# STM32L4P5 register map
File version: 1.8
CPU: CM4 r0p1, little endian, MPU, FPU, 4 interrupt priority bits
Registers are 32-bit, read-write, reset 0x0 unless marked. A register's access mark holds for its fields unless they carry their own. Offsets are from the block's base; [hi:lo] are bit positions; 'fields as' and 'values as' point back to an identical list.

## IWDG — Independent watchdog
Base 0x40003000
0x00 KR wo — Key register
  [15:0] KEY — Key value (write only, read 0x0000)
    0x5555=Unlock (Enable access to PR, RLR and WINR registers); 0xAAAA=Feed watchdog with RLR register value; 0xCCCC=Start the watchdog
0x04 PR — Prescaler register
  [2:0] PR — Prescaler divider
    0=DivideBy4 (Divider /4); 1=DivideBy8 (Divider /8); 2=DivideBy16 (Divider /16); 3=DivideBy32 (Divider /32); 4=DivideBy64 (Divider /64); 5=DivideBy128 (Divider /128); other=DivideBy256 (Divider /256)
0x08 RLR reset 0xFFF — Reload register
  [11:0] RL — Watchdog counter reload value
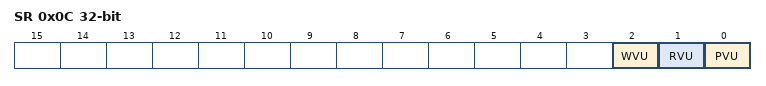
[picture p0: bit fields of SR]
0x0C SR ro — Status register
  [2] WVU — Watchdog counter window value update
  [1] RVU — Watchdog counter reload value update
  [0] PVU — Watchdog prescaler value update
0x10 WINR reset 0xFFF — Window register
  [11:0] WIN — Watchdog counter window value

## WWDG — System window watchdog
Base 0x40002C00
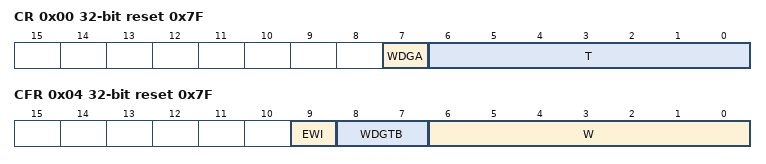
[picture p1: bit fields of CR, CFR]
0x00 CR reset 0x7F — Control register
  [7] WDGA — Activation bit
    0=Disabled (Watchdog disabled); 1=Enabled (Watchdog enabled)
  [6:0] T — 7-bit counter (MSB to LSB)
0x04 CFR reset 0x7F — Configuration register
  [9] EWI — Early wakeup interrupt
    on write: 1=Enable (interrupt occurs whenever the counter reaches the value 0x40)
  [8:7] WDGTB — Timer base
    0=Div1 (Counter clock (PCLK1 div 4096) div 1); 1=Div2 (Counter clock (PCLK1 div 4096) div 2); 2=Div4 (Counter clock (PCLK1 div 4096) div 4); 3=Div8 (Counter clock (PCLK1 div 4096) div 8)
  [6:0] W — 7-bit window value
0x08 SR — Status register
  [0] EWIF write-0-clears — Early wakeup interrupt flag
    on read: 0=Finished (The EWI Interrupt Service Routine has been serviced); 1=Pending (The EWI Interrupt Service Routine has been triggered) | on write: 0=Finished (The EWI Interrupt Service Routine has been serviced)

## COMP — Comparator
Base 0x40010200
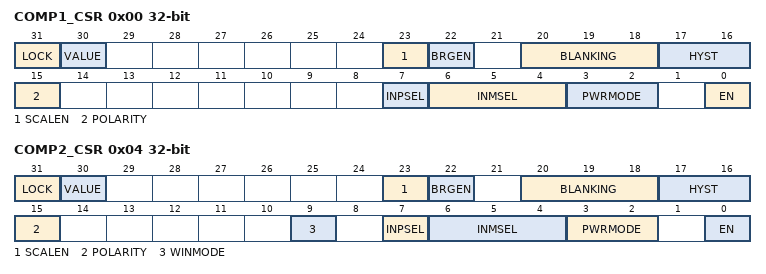
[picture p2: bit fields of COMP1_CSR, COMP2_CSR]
0x00 COMP1_CSR access per field — Comparator 1 control and status register
  [31] LOCK wo — COMP1_CSR register lock bit
    0=Unlocked (Comparator CSR bits are read-write); 1=Locked (Comparator CSR bits are read-only)
  [30] VALUE ro — Comparator 1 output status bit
    0=Low (Comparator output is low); 1=High (Comparator output is high)
  [23] SCALEN rw — Voltage scaler enable bit
    0=Disabled (Voltage scaler disabled); 1=Enabled (Voltage scaler enabled)
  [22] BRGEN rw — Scaler bridge enable
    0=Disabled (Scaler resistor bridge disabled); 1=Enabled (Scaler resistor bridge enabled)
  [20:18] BLANKING rw — Comparator 1 blanking source selection bits
    0=Disabled (No blanking); 1=TIM1OC5 (TIM1 OC5 selected as blanking source); 2=TIM2OC3 (TIM2 OC3 selected as blanking source)
  [17:16] HYST rw — Comparator 1 hysteresis selection bits
    0=None (No hysteresis); 1=Low (Low hysteresis); 2=Medium hysteresis; 3=High hysteresis
  [15] POLARITY rw — Comparator 1 polarity selection bit
    0=Normal (Comparator X output value not inverted); 1=Inverted (Comparator X output value inverted)
  [7] INPSEL rw — Comparator1 input plus selection bit
    0=external IO - PC5; 1=PB2
  [6:4] INMSEL rw — Comparator 1 Input Minus connection configuration bit
  [3:2] PWRMODE rw — Power Mode of the comparator 1
    0=High speed; 1=Medium speed; 3=Low (Ultra low power)
  [0] EN rw — Comparator 1 enable bit
    0=Disabled (Comparator X disabled); 1=Enabled (Comparator X enabled)
0x04 COMP2_CSR access per field — Comparator 2 control and status register
  [31] LOCK wo — COMP2_CSR register lock bit
    values as COMP1_CSR.LOCK
  [30] VALUE ro — Comparator 2 output status bit
    values as COMP1_CSR.VALUE
  [23] SCALEN rw — Voltage scaler enable bit
    values as COMP1_CSR.SCALEN
  [22] BRGEN rw — Scaler bridge enable
    values as COMP1_CSR.BRGEN
  [20:18] BLANKING rw — Comparator 2 blanking source selection bits
    0=Disabled (No blanking); 4=TIM15OC1 (TIM15 OC1 selected as blanking source)
  [17:16] HYST rw — Comparator 2 hysteresis selection bits
    values as COMP1_CSR.HYST
  [15] POLARITY rw — Comparator 2 polarity selection bit
    values as COMP1_CSR.POLARITY
  [9] WINMODE rw — Windows mode selection bit
    0=Disabled (Input plus of Comparator 2 is not connected to Comparator 1); 1=Enabled (Input plus of Comparator 2 is connected with input plus of Comparator 1)
  [7] INPSEL rw — Comparator 2 Input Plus connection configuration bit
    0=PB4; 1=PB6
  [6:4] INMSEL rw — Comparator 2 Input Minus connection configuration bit
  [3:2] PWRMODE rw — Power Mode of the comparator 2
    0=High speed; 1=Medium speed; 3=Low (Ultra low power)
  [0] EN rw — Comparator 2 enable bit
    values as COMP1_CSR.EN
